# H6 register map
Vendor: Allwinner; Series: H6; File version: 0.1
CPU: CA53 0, little endian, MPU, no FPU, 0 interrupt priority bits
Registers are 32-bit, read-write, reset 0x0 unless marked. A register's access mark holds for its fields unless they carry their own. Offsets are from the block's base; [hi:lo] are bit positions.

## CIR_TX
Base 0x05070400
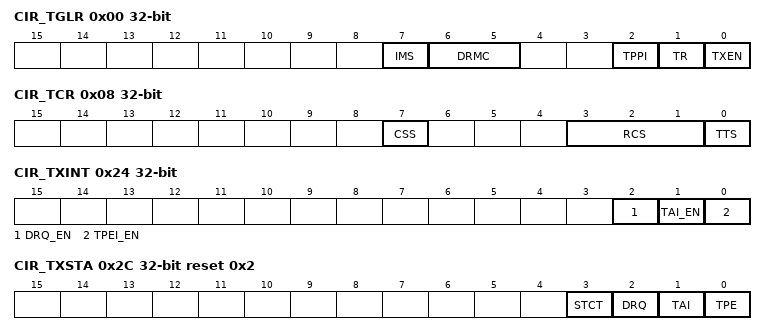
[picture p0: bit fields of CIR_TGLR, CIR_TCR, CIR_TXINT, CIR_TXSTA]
0x00 CIR_TGLR — CIR Transmit Global Register
  [7] IMS — Internal Modulation Select 0: the transmitting signal is not modulated 1: the transmitting signal is modulated internally
    0=not_modulated (the transmitting signal is not modulated); 1=modulated (the transmitting signal is modulated internally)
  [6:5] DRMC — Duty ratio of modulated carrier is high level /low level. 00: low level is the one time of high level 01: low level is the two times of high level 10: low level is the three times of high level 11: reserved
    0=the_one (low level is the one time of high level); 1=the_two (low level is the two times of high level); 2=the_three (low level is the three times of high level)
  [2] TPPI — Transmit Pulse Polarity Invert 0: Not invert transmit pulse 1: Invert transmit pulse
    0=Not invert transmit pulse; 1=Invert transmit pulse
  [1] TR — Transmit Reset When this bit is set, the transmitting is reset. The FIFO will be flush, the TIC filed and CSS field will be clean during Transmit Reset. This field will automatically clear when the Transmit Reset is finished, and the CIR transmitter will state Idle .
  [0] TXEN — Transmit Block Enable 0: Disable the CIR Transmitter 1: Enable the CIR Transmitter
    0=Disable the CIR Transmitter; 1=Enable the CIR Transmitter
0x04 CIR_TMCR reset 0x9E — CIR Transmit Modulation Control Register
  [7:0] RFMC — Reference Frequency of modulated carrier. Reference Frequency of modulated carrier based on a division of a fixed functional clock(FCLK).The range of the modulated carrier is usually 30kHz to 60kHz. The most consumer electronics is 38kHz. The default modulated carrier is 38kHz when FCLK is 6MHz. RFMC= FCLK/N.
0x08 CIR_TCR — CIR Transmit Control Register
  [7] CSS — Cyclical Pulse Start/Stop Control Start to transmit when set to '1', 0: Stop when cleared to '0'. From start to stop, all data in FIFO must be transmitted. 1: Start.
    0=Stop when cleared to '0'. From start to stop, all data in FIFO must be transmitted.; 1=Start
  [3:1] RCS — Reference Clock Select for CIR Transmit 000: CIR Transmit reference clock is ir_clk 001: CIR Transmit reference clock is ir_clk/2 010: CIR Transmit reference clock is ir_clk/4 011: CIR Transmit reference clock is ir_clk/8 100: CIR Transmit reference clock is ir_clk/64 101: CIR Transmit reference clock is ir_clk/128 110: CIR Transmit reference clock is ir_clk/256 111: CIR Transmit reference clock is ir_clk/512
    0=ir_clk (CIR Transmit reference clock is ir_clk); 1=ir_clk_slash_2 (CIR Transmit reference clock is ir_clk/2); 2=ir_clk_slash_4 (CIR Transmit reference clock is ir_clk/4); 3=ir_clk_slash_8 (CIR Transmit reference clock is ir_clk/8); 4=ir_clk_slash_64 (CIR Transmit reference clock is ir_clk/64); 5=ir_clk_slash_128 (CIR Transmit reference clock is ir_clk/128); 6=ir_clk_slash_256 (CIR Transmit reference clock is ir_clk/256); 7=ir_clk_slash_512 (CIR Transmit reference clock is ir_clk/512)
  [0] TTS — Type of the transmission signal 0: The transmitting wave is single non-cyclical pulse. 1: The transmitting wave is cyclical short-pulse.
    0=single (The transmitting wave is single non-cyclical pulse.); 1=cyclical (The transmitting wave is cyclical short-pulse.)
0x0C CIR_IDC_H — CIR Transmit Idle Duration Threshold Register
  [3:0] IDC_H — Idle Duration Counter threshold(High 4 bit) Idle Duration = 128*IDC*Ts (IDC = 0~4095)
0x10 CIR_IDC_L — CIR Transmit Idle Duration Threshold Register
  [7:0] IDC_L — Idle Duration Counter threshold(Low 8 bit) Idle Duration = 128*IDC*Ts (IDC = 0~4095)
0x14 CIR_TICR_H — CIR Transmit Idle Counter Register
  [7:0] TIC_H ro — Transmit Idle Counter_H(High 8 bit) Count in 128*Ts (Sample Duration, 1/Fs) when transmitter is idle, and it should be reset when the transmitter active. When this counter reaches the maximum value (0xFFFF), it will stop automatically, and should not be cleared to zero.
0x18 CIR_TICR_L — CIR Transmit Idle Counter Register
  [7:0] TIC_L ro — Transmit Idle Counter_L(Low 8 bit) Count in 128*Ts (Sample Duration, 1/Fs) when transmitter is idle, and it should be reset when the transmitter active. When this counter reaches the maximum value (0xFFFF), it will stop automatically, and should not be cleared to zero.
0x20 CIR_TEL — CIR TX FIFO empty Level Register
  [7:0] TEL — TX FIFO empty Level for DRQ and IRQ. TRIGGER_LEVEL = TEL + 1
0x24 CIR_TXINT — CIR Transmit Interrupt Control Register
  [2] DRQ_EN — TX FIFO DMA Enable 0: Disable 1: Enable When set to `1`, the Tx FIFO DRQ is asserted if the number of the transmitting data in the FIFO is less than the RAL. The DRQ is de-asserted when condition fails.
    0=Disable; 1=Enable When set to `1`, the Tx FIFO DRQ is asserted if the number of the transmitting data in the FIFO is less than the RAL. The DRQ is de-asserted when condition fails.
  [1] TAI_EN — TX FIFO Available Interrupt Enable 0:Disable 1:Enable
  [0] TPEI_EN — Transmit Packet End Interrupt Enable for Cyclical Pulse 0:Disable 1:Enable TUI_EN Transmitter FIFO under run Interrupt Enable for Non-cyclical Pulse 0: Disable 1: Enable
    0=Disable; 1=Enable
0x28 CIR_TAC reset 0x80 — CIR Transmit FIFO Available Counter Register
  [7:0] TAC ro — TX FIFO Available Space Counter 0x00: No available space in TX FIFO 0x01: 1 byte available space in TX FIFO 0x02: 2 byte available space in TX FIFO ... 0x80: 128 byte available space in TX FIFO
    0=No available space in TX FIFO; 1=1 byte available space in TX FIFO; 2=2 byte available space in TX FIFO ; 128=128 byte available space in TX FIFO
0x2C CIR_TXSTA reset 0x2 — CIR Transmit Status Register
  [3] STCT ro — Status of CIR Transmitter 0x0:Idle 0x1:Active This bit will automatically set when the controller begins transmit the data in the FIFO. The `1` will last when the data in the FIFO. It will automatically be cleaned to `0` when all data in the FIFO is transmitted. The bit is for debug.
  [2] DRQ ro — DMA Request Flag When set to `1`, the Tx FIFO DRQ is asserted if the number of the transmitting data in the FIFO is less than the RAL. The DRQ is de-asserted when condition fails. This bit is for debug.
  [1] TAI — TX FIFO Available Interrupt Flag 0: TX FIFO not available by its level 1: TX FIFO available by its level This bit can be cleared by software writing `1`.
    0=TX_FIFO (TX FIFO not available by its level); 1=TX FIFO available by its level This bit can be cleared by software writing `1`
  [0] TPE — Transmitter Packet End Flag for Cyclical Pulse 0: Transmissions of address, control and data fields not completed 1: Transmissions of address, control and data fields completed TUR Transmitter FIFO Under Run Flag for Non-cyclical Pulse 0: No transmitter FIFO under run 1: Transmitter FIFO under run This bit is cleared by writing a `1`.
0x30 CIR_TXT — CIR Transmit Threshold Register
  [7:0] NCTT — Non-cyclical Pulse Transmit Threshold The controller will trigger transmitting the data in the FIFO when the data byte number has reaches the Transmit Threshold set in this field.
0x34 CIR_DMA_CTL reset 0xA5
  [7:0] DMA — Handshake Configuration 0xA5: DMA wait cycle mode 0xEA: DMA handshake mode
    165=wait_cycle (DMA wait cycle mode); 234=handshake_mode (DMA handshake mode)
0x80 CIR_TXFIFO — CIR Transmit FIFO Data Register
  [7:0] TRANSMIT wo — Transmit Byte FIFO When the transmitting is trigger, the data in the FIFO will be transmitted until the data number is finished to be transmitted.
